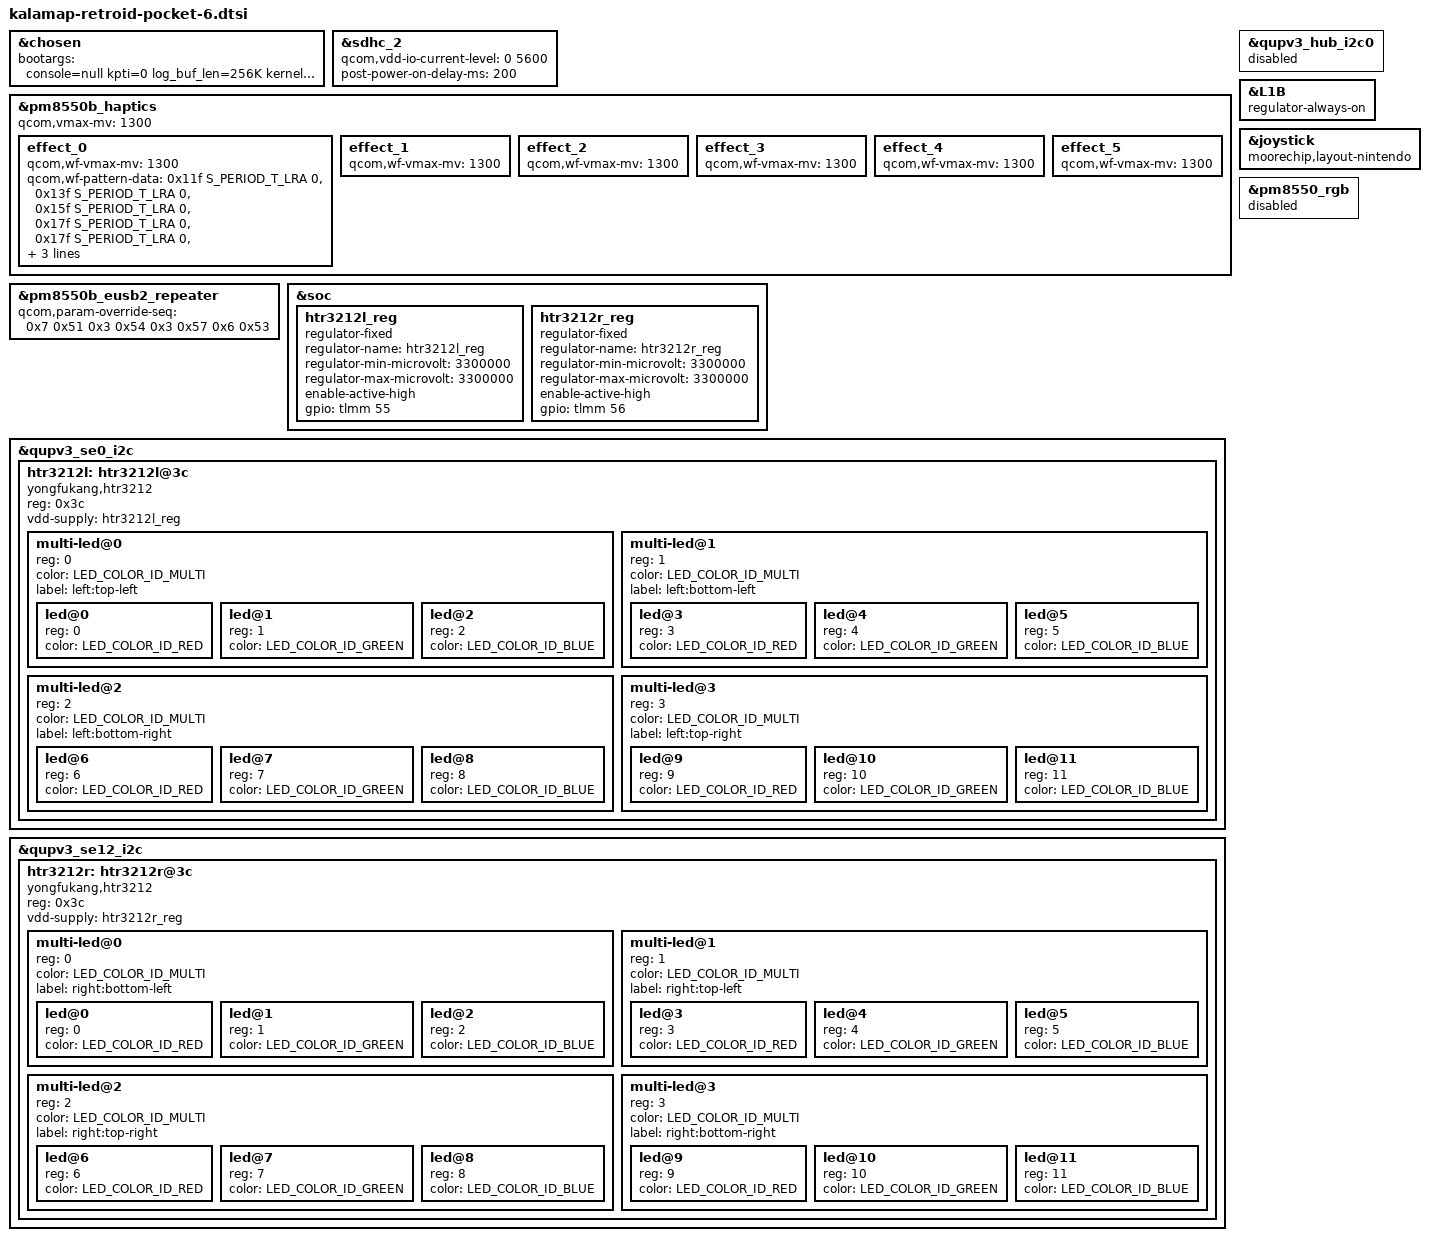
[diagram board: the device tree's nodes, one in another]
#include "kalamap-moorechip-common.dtsi"
#include "kalamap-moorechip-joystick-mappable.dtsi"
#include <dt-bindings/leds/common.h>

&chosen {
	bootargs = "console=null kpti=0 log_buf_len=256K kernel.panic_on_rcu_stall=1 service_locator.enable=1 msm_rtb.filter=0x237 rcupdate.rcu_expedited=1 rcu_nocbs=0-7 ftrace_dump_on_oops swiotlb=noforce loop.max_part=7 fw_devlink.strict=1 allow_mismatched_32bit_el0 cpufreq.default_governor=performance printk.console_no_auto_verbose=1 kasan=off sysctl.kernel.sched_pelt_multiplier=4 can.stats_timer=0 pcie_ports=compat irqaffinity=0-2 disable_dma32=on no-steal-acc cgroup.memory=nokmem,nosocket slub_debug=- msm_drm.moorechip_dsi_display0=qcom,mdss_dsi_vtdr6130_visionox_cog_cmd:";
};

&sdhc_2 {
	qcom,vdd-io-current-level = <0 5600>;
	post-power-on-delay-ms = <200>;
};

&pm8550b_haptics {
	qcom,vmax-mv = <1300>;

	effect_0 {
		/* CLICK */
		qcom,wf-vmax-mv = <1300>;
		qcom,wf-pattern-data =  <0x11f  S_PERIOD_T_LRA  0>,
					<0x13f  S_PERIOD_T_LRA  0>,
					<0x15f  S_PERIOD_T_LRA  0>,
					<0x17f  S_PERIOD_T_LRA  0>,
					<0x17f  S_PERIOD_T_LRA  0>,
					<0x15f  S_PERIOD_T_LRA  0>,
					<0x13f  S_PERIOD_T_LRA  0>,
					<0x11f  S_PERIOD_T_LRA  0>;
		/delete-property/ qcom,wf-pattern-preload;
	};

	effect_1 {
		/* DOUBLE_CLICK */
		qcom,wf-vmax-mv = <1300>;
	};

	effect_2 {
		/* TICK */
		qcom,wf-vmax-mv = <1300>;
	};

	effect_3 {
		/* THUD */
		qcom,wf-vmax-mv = <1300>;
	};

	effect_4 {
		/* POP */
		qcom,wf-vmax-mv = <1300>;
	};

	effect_5 {
		/* HEAVY CLICK */
		qcom,wf-vmax-mv = <1300>;
	};
};

&pm8550b_eusb2_repeater {
	qcom,param-override-seq =
		/* <value reg_offset> */
		/* Adjust HS trasmit amplitude */
		<0x7 0x51
		/* Squelch detection threshold */
		 0x3 0x54
		/* Tx pre-emphasis tuning */
		 0x3 0x57
		/* HS disconnect threshold */
		 0x6 0x53>;
};

&qupv3_hub_i2c0 {
	status = "disabled";
};

&soc {
	htr3212l_reg: htr3212l_reg {
		compatible = "regulator-fixed";
		regulator-name = "htr3212l_reg";
		regulator-min-microvolt = <3300000>;
		regulator-max-microvolt = <3300000>;
		enable-active-high;
		gpio = <&tlmm 55 GPIO_ACTIVE_HIGH>;
	};
};

&qupv3_se0_i2c {
	#address-cells = <1>;
	#size-cells = <0>;
	status = "ok";

	htr3212l: htr3212l@3c {
		compatible = "yongfukang,htr3212";
		reg = <0x3c>;
		vdd-supply = <&htr3212l_reg>;

		multi-led@0 {
			#address-cells = <1>;
			#size-cells = <0>;
			reg = <0>;
			color = <LED_COLOR_ID_MULTI>;
			label = "left:top-left";

			led@0 {
				reg = <0>;
				color = <LED_COLOR_ID_RED>;
			};

			led@1 {
				reg = <1>;
				color = <LED_COLOR_ID_GREEN>;
			};

			led@2 {
				reg = <2>;
				color = <LED_COLOR_ID_BLUE>;
			};
		};

		multi-led@1 {
			#address-cells = <1>;
			#size-cells = <0>;
			reg = <1>;
			color = <LED_COLOR_ID_MULTI>;
			label = "left:bottom-left";

			led@3 {
				reg = <3>;
				color = <LED_COLOR_ID_RED>;
			};

			led@4 {
				reg = <4>;
				color = <LED_COLOR_ID_GREEN>;
			};

			led@5 {
				reg = <5>;
				color = <LED_COLOR_ID_BLUE>;
			};
		};

		multi-led@2 {
			#address-cells = <1>;
			#size-cells = <0>;
			reg = <2>;
			color = <LED_COLOR_ID_MULTI>;
			label = "left:bottom-right";

			led@6 {
				reg = <6>;
				color = <LED_COLOR_ID_RED>;
			};

			led@7 {
				reg = <7>;
				color = <LED_COLOR_ID_GREEN>;
			};

			led@8 {
				reg = <8>;
				color = <LED_COLOR_ID_BLUE>;
			};
		};

		multi-led@3 {
			#address-cells = <1>;
			#size-cells = <0>;
			reg = <3>;
			color = <LED_COLOR_ID_MULTI>;
			label = "left:top-right";

			led@9 {
				reg = <9>;
				color = <LED_COLOR_ID_RED>;
			};

			led@10 {
				reg = <10>;
				color = <LED_COLOR_ID_GREEN>;
			};

			led@11 {
				reg = <11>;
				color = <LED_COLOR_ID_BLUE>;
			};
		};
	};
};

&soc {
	htr3212r_reg: htr3212r_reg {
		compatible = "regulator-fixed";
		regulator-name = "htr3212r_reg";
		regulator-min-microvolt = <3300000>;
		regulator-max-microvolt = <3300000>;
		enable-active-high;
		gpio = <&tlmm 56 GPIO_ACTIVE_HIGH>;
	};
};

&qupv3_se12_i2c {
	#address-cells = <1>;
	#size-cells = <0>;
	status = "ok";

	htr3212r: htr3212r@3c {
		compatible = "yongfukang,htr3212";
		reg = <0x3c>;
		vdd-supply = <&htr3212r_reg>;

		multi-led@0 {
			#address-cells = <1>;
			#size-cells = <0>;
			reg = <0>;
			color = <LED_COLOR_ID_MULTI>;
			label = "right:bottom-left";

			led@0 {
				reg = <0>;
				color = <LED_COLOR_ID_RED>;
			};

			led@1 {
				reg = <1>;
				color = <LED_COLOR_ID_GREEN>;
			};

			led@2 {
				reg = <2>;
				color = <LED_COLOR_ID_BLUE>;
			};
		};

		multi-led@1 {
			#address-cells = <1>;
			#size-cells = <0>;
			reg = <1>;
			color = <LED_COLOR_ID_MULTI>;
			label = "right:top-left";

			led@3 {
				reg = <3>;
				color = <LED_COLOR_ID_RED>;
			};

			led@4 {
				reg = <4>;
				color = <LED_COLOR_ID_GREEN>;
			};

			led@5 {
				reg = <5>;
				color = <LED_COLOR_ID_BLUE>;
			};
		};

		multi-led@2 {
			#address-cells = <1>;
			#size-cells = <0>;
			reg = <2>;
			color = <LED_COLOR_ID_MULTI>;
			label = "right:top-right";

			led@6 {
				reg = <6>;
				color = <LED_COLOR_ID_RED>;
			};

			led@7 {
				reg = <7>;
				color = <LED_COLOR_ID_GREEN>;
			};

			led@8 {
				reg = <8>;
				color = <LED_COLOR_ID_BLUE>;
			};
		};

		multi-led@3 {
			#address-cells = <1>;
			#size-cells = <0>;
			reg = <3>;
			color = <LED_COLOR_ID_MULTI>;
			label = "right:bottom-right";

			led@9 {
				reg = <9>;
				color = <LED_COLOR_ID_RED>;
			};

			led@10 {
				reg = <10>;
				color = <LED_COLOR_ID_GREEN>;
			};

			led@11 {
				reg = <11>;
				color = <LED_COLOR_ID_BLUE>;
			};
		};
	};
};

// TODO: Unknown, but removal of this breaks booting recovery.
&L1B {
	regulator-always-on;
};

&joystick {
	moorechip,layout-nintendo;
};

&pm8550_rgb {
	status = "disabled";
};
